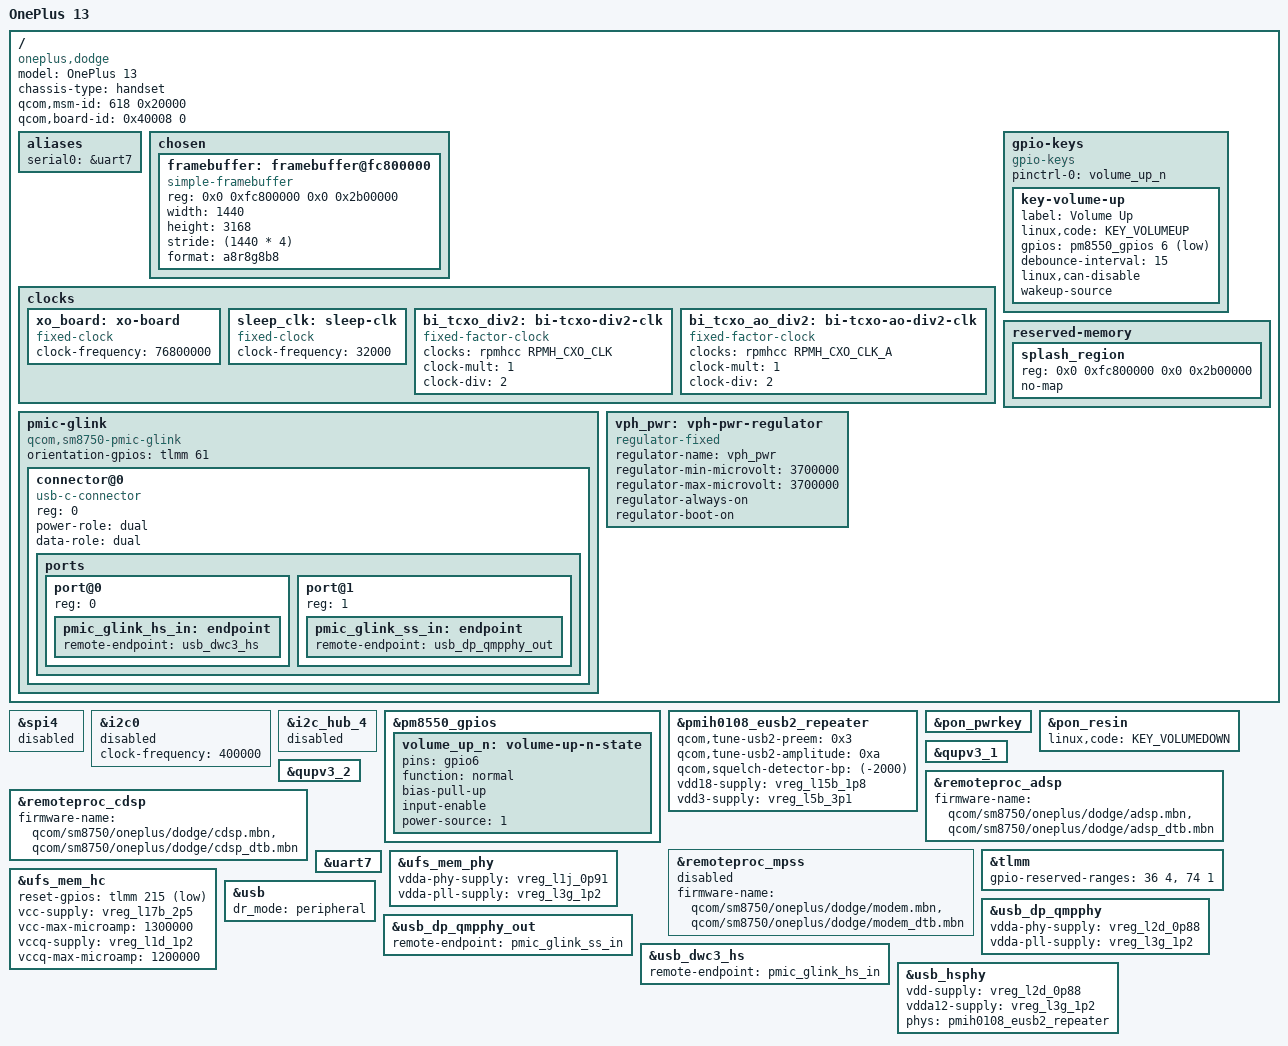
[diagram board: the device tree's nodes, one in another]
// SPDX-License-Identifier: BSD-3-Clause
/*
 * OnePlus 13 ("dodge", OPLUS projects 23821 / 23893 / 23894 / 23895)
 *
 * Bring-up device tree for mainline Linux. It was put together by reading
 * the downstream OnePlus device tree (OnePlusOSS
 * android_kernel_modules_and_devicetree_oneplus_sm8750, branch
 * oneplus/sm8750_b_16.0.0_oneplus_13), whose board files are overlays on
 * Qualcomm's "sun-mtp-v8" reference design. Each hardware fact below names
 * the downstream file it came from. docs/hardware.md has the full table.
 *
 * Status: stage 1 (boot to a shell). Display is the bootloader framebuffer;
 * storage is UFS; USB runs in peripheral mode so the board can be reached
 * over USB networking / serial gadget.
 */

/dts-v1/;

#include <dt-bindings/gpio/gpio.h>
#include <dt-bindings/regulator/qcom,rpmh-regulator.h>
#include "sm8750.dtsi"
#include "pm8010.dtsi"
#include "pm8550.dtsi"
#define PMK8550VE_SID 8
#include "pm8550ve.dtsi"
#include "pmd8028.dtsi"
#include "pmih0108.dtsi"
#include "pmk8550.dtsi"
#include "pmr735d_a.dtsi"
#include "sm8750-pmics.dtsi"

/ {
	model = "OnePlus 13";
	compatible = "oneplus,dodge", "qcom,sm8750";
	chassis-type = "handset";

	/*
	 * ABL picks the DTB whose msm-id / board-id match the hardware.
	 * Values are from downstream qcom/sun-v2.dtsi (SM8750 v2 = 618) and
	 * qcom/sun-mtp-v8-overlay.dts (board-id 0x40008: MTP, subtype 4).
	 * Confirm against /proc/device-tree/qcom,{msm,board}-id on the stock
	 * firmware (scripts/dump-live-device.sh collects them).
	 */
	qcom,msm-id = <618 0x20000>;
	qcom,board-id = <0x40008 0>;

	aliases {
		serial0 = &uart7;
	};

	chosen {
		#address-cells = <2>;
		#size-cells = <2>;
		ranges;

		/*
		 * Framebuffer left running by ABL. Region from downstream
		 * display/sun-sde-display.dtsi "cont_splash_region"; the panel
		 * is 1440x3168 (oplus/panel/dsi-panel-AA569-P-3-A0019-dsc-cmd.dtsi).
		 */
		framebuffer: framebuffer@fc800000 {
			compatible = "simple-framebuffer";
			reg = <0x0 0xfc800000 0x0 0x2b00000>;
			width = <1440>;
			height = <3168>;
			stride = <(1440 * 4)>;
			format = "a8r8g8b8";
		};
	};

	clocks {
		xo_board: xo-board {
			compatible = "fixed-clock";
			clock-frequency = <76800000>;
			#clock-cells = <0>;
		};

		sleep_clk: sleep-clk {
			compatible = "fixed-clock";
			clock-frequency = <32000>;
			#clock-cells = <0>;
		};

		bi_tcxo_div2: bi-tcxo-div2-clk {
			compatible = "fixed-factor-clock";
			#clock-cells = <0>;

			clocks = <&rpmhcc RPMH_CXO_CLK>;
			clock-mult = <1>;
			clock-div = <2>;
		};

		bi_tcxo_ao_div2: bi-tcxo-ao-div2-clk {
			compatible = "fixed-factor-clock";
			#clock-cells = <0>;

			clocks = <&rpmhcc RPMH_CXO_CLK_A>;
			clock-mult = <1>;
			clock-div = <2>;
		};
	};

	gpio-keys {
		compatible = "gpio-keys";

		pinctrl-0 = <&volume_up_n>;
		pinctrl-names = "default";

		key-volume-up {
			label = "Volume Up";
			linux,code = <KEY_VOLUMEUP>;
			gpios = <&pm8550_gpios 6 GPIO_ACTIVE_LOW>;
			debounce-interval = <15>;
			linux,can-disable;
			wakeup-source;
		};

		/* TODO: alert slider (three-position hall switch). */
	};

	pmic-glink {
		compatible = "qcom,sm8750-pmic-glink",
			     "qcom,sm8550-pmic-glink",
			     "qcom,pmic-glink";
		#address-cells = <1>;
		#size-cells = <0>;
		orientation-gpios = <&tlmm 61 GPIO_ACTIVE_HIGH>;

		connector@0 {
			compatible = "usb-c-connector";
			reg = <0>;

			power-role = "dual";
			data-role = "dual";

			ports {
				#address-cells = <1>;
				#size-cells = <0>;

				port@0 {
					reg = <0>;

					pmic_glink_hs_in: endpoint {
						remote-endpoint = <&usb_dwc3_hs>;
					};
				};

				port@1 {
					reg = <1>;

					pmic_glink_ss_in: endpoint {
						remote-endpoint = <&usb_dp_qmpphy_out>;
					};
				};
			};
		};
	};

	reserved-memory {
		/*
		 * ABL keeps the display pipeline (and the splash framebuffer)
		 * alive only if it finds a region with this exact name, the same
		 * one the downstream DT uses.
		 */
		splash_region {
			reg = <0x0 0xfc800000 0x0 0x2b00000>;
			no-map;
		};
	};

	vph_pwr: vph-pwr-regulator {
		compatible = "regulator-fixed";

		regulator-name = "vph_pwr";
		regulator-min-microvolt = <3700000>;
		regulator-max-microvolt = <3700000>;

		regulator-always-on;
		regulator-boot-on;
	};
};

#include "sm8750-oneplus-dodge-regulators.dtsi"

/* Touchscreen: Synaptics S3910 (TouchComm) on SPI4, oplus/tp/dodge-oplus-tp-23821.dtsi */
&spi4 {
	/*
	 * Downstream: irq tlmm 162, reset tlmm 161, AVDD switched by
	 * pm8550vs_j gpio3, VDD = L4B. Mainline has no TouchComm (TCM) driver
	 * yet, and the chip does not speak RMI4, so this stays disabled until
	 * a driver exists.
	 */
	status = "disabled";
};

/* NFC: NXP SN-series on I2C0 @ 0x28, oplus/oplus_nfc/dodge_nfc.dtsi */
&i2c0 {
	clock-frequency = <400000>;

	/* irq tlmm 75, VEN tlmm 34, CLKREQ tlmm 35, VBAT tlmm 174 */
	status = "disabled";
};

/* Speaker amps: 2x Awinic AW882xx on I2C hub 4 @ 0x34/0x35, reset tlmm 2/164 */
&i2c_hub_4 {
	status = "disabled";
};

&pm8550_gpios {
	volume_up_n: volume-up-n-state {
		pins = "gpio6";
		function = "normal";
		bias-pull-up;
		input-enable;
		power-source = <1>;
	};
};

&pmih0108_eusb2_repeater {
	qcom,tune-usb2-preem = /bits/ 8 <0x3>;
	qcom,tune-usb2-amplitude = /bits/ 8 <0xa>;
	qcom,squelch-detector-bp = <(-2000)>;

	vdd18-supply = <&vreg_l15b_1p8>;
	vdd3-supply = <&vreg_l5b_3p1>;

	status = "okay";
};

&pon_pwrkey {
	status = "okay";
};

&pon_resin {
	linux,code = <KEY_VOLUMEDOWN>;

	status = "okay";
};

&qupv3_1 {
	status = "okay";
};

&qupv3_2 {
	status = "okay";
};

/*
 * Co-processor firmware: signed blobs taken from the stock firmware by
 * scripts/extract-firmware.sh. They load from the device-specific
 * directory because OEMs sign their own images.
 */
&remoteproc_adsp {
	firmware-name = "qcom/sm8750/oneplus/dodge/adsp.mbn",
			"qcom/sm8750/oneplus/dodge/adsp_dtb.mbn";

	status = "okay";
};

&remoteproc_cdsp {
	firmware-name = "qcom/sm8750/oneplus/dodge/cdsp.mbn",
			"qcom/sm8750/oneplus/dodge/cdsp_dtb.mbn";

	status = "okay";
};

&remoteproc_mpss {
	firmware-name = "qcom/sm8750/oneplus/dodge/modem.mbn",
			"qcom/sm8750/oneplus/dodge/modem_dtb.mbn";

	/* Disabled upstream on the MTP as well (watchdog during init). */
	status = "disabled";
};

&tlmm {
	/* Reserved for the secure world (same as MTP; TZ faults on access). */
	gpio-reserved-ranges = <36 4>, <74 1>;
};

&uart7 {
	/* Debug UART (downstream qupv3_se7_2uart); only on test pads. */
	status = "okay";
};

&ufs_mem_phy {
	vdda-phy-supply = <&vreg_l1j_0p91>;
	vdda-pll-supply = <&vreg_l3g_1p2>;

	status = "okay";
};

&ufs_mem_hc {
	reset-gpios = <&tlmm 215 GPIO_ACTIVE_LOW>;

	vcc-supply = <&vreg_l17b_2p5>;
	vcc-max-microamp = <1300000>;
	vccq-supply = <&vreg_l1d_1p2>;
	vccq-max-microamp = <1200000>;

	status = "okay";
};

&usb {
	/*
	 * Stage 1: force peripheral mode so USB networking works before the
	 * ADSP (and so pmic-glink role switching) is up. Drop this once
	 * pmic-glink is confirmed working, to get dual-role / host mode.
	 */
	dr_mode = "peripheral";

	status = "okay";
};

&usb_dp_qmpphy {
	vdda-phy-supply = <&vreg_l2d_0p88>;
	vdda-pll-supply = <&vreg_l3g_1p2>;

	status = "okay";
};

&usb_dp_qmpphy_out {
	remote-endpoint = <&pmic_glink_ss_in>;
};

&usb_dwc3_hs {
	remote-endpoint = <&pmic_glink_hs_in>;
};

&usb_hsphy {
	vdd-supply = <&vreg_l2d_0p88>;
	vdda12-supply = <&vreg_l3g_1p2>;

	phys = <&pmih0108_eusb2_repeater>;

	status = "okay";
};
